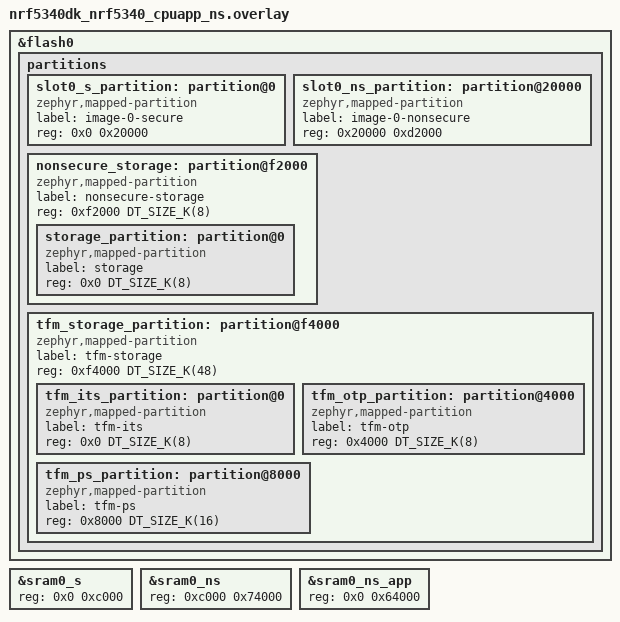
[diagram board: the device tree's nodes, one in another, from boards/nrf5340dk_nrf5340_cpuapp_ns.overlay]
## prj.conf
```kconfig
CONFIG_LOG=y

# Button and LED library
CONFIG_DK_LIBRARY=y
CONFIG_BT_LBS=y

CONFIG_BT=y
CONFIG_BT_DEVICE_NAME="Lamb_Idea_DK"

#  Include the Peripheral Role support
CONFIG_BT_PERIPHERAL=y

# Increase stack size for the main thread, System Workqueue, BT RX thread and TX buf count
CONFIG_SYSTEM_WORKQUEUE_STACK_SIZE=2048
CONFIG_MAIN_STACK_SIZE=2048
CONFIG_BT_RX_STACK_SIZE=2048
CONFIG_BT_BUF_CMD_TX_COUNT=2
```

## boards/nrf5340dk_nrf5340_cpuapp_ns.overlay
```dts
/*
 * Copyright (c) 2026 Nordic Semiconductor ASA
 *
 * SPDX-License-Identifier: LicenseRef-Nordic-5-Clause
 */

 /delete-node/ &boot_partition;
 /delete-node/ &slot0_partition;
 /delete-node/ &slot1_partition;
 /delete-node/ &tfm_its_partition;
 /delete-node/ &tfm_otp_partition;
 /delete-node/ &tfm_ps_partition;
 /delete-node/ &storage_partition;

 &flash0 {
	 partitions {
		 slot0_s_partition: partition@0 {
			 compatible = "zephyr,mapped-partition";
			 label = "image-0-secure";
			 reg = <0x0 0x20000>;
		 };

		 slot0_ns_partition: partition@20000 {
			 compatible = "zephyr,mapped-partition";
			 label = "image-0-nonsecure";
			 reg = <0x20000 0xd2000>;
		 };

		 nonsecure_storage: partition@f2000 {
			 compatible = "zephyr,mapped-partition";
			 label = "nonsecure-storage";
			 reg = <0xf2000 DT_SIZE_K(8)>;
			 ranges = <0x0 0xf2000 DT_SIZE_K(8)>;
			 #address-cells = <1>;
			 #size-cells = <1>;

			 storage_partition: partition@0 {
				 compatible = "zephyr,mapped-partition";
				 label = "storage";
				 reg = <0x0 DT_SIZE_K(8)>;
			 };
		 };

		 tfm_storage_partition: partition@f4000 {
			 compatible = "zephyr,mapped-partition";
			 label = "tfm-storage";
			 reg = <0xf4000 DT_SIZE_K(48)>;
			 ranges = <0x0 0xf4000 DT_SIZE_K(48)>;
			 #address-cells = <1>;
			 #size-cells = <1>;

			 tfm_its_partition: partition@0 {
				 compatible = "zephyr,mapped-partition";
				 label = "tfm-its";
				 reg = <0x0 DT_SIZE_K(8)>;
			 };

			 tfm_otp_partition: partition@4000 {
				 compatible = "zephyr,mapped-partition";
				 label = "tfm-otp";
				 reg = <0x4000 DT_SIZE_K(8)>;
			 };

			 tfm_ps_partition: partition@8000 {
				 compatible = "zephyr,mapped-partition";
				 label = "tfm-ps";
				 reg = <0x8000 DT_SIZE_K(16)>;
			 };
		 };
	 };
 };

 /*
  * TrustZone SRAM split from devicetree (region_defs.h for TF-M). The secure image uses
  * 48 KiB (0xc000) at the base of cpuapp SRAM (&sram0_s); NS RAM begins at 0x20000000 + 0xc000.
  * &sram0_ns spans 0x74000 bytes; &sram0_ns_app is 0x64000 because the top 0x10000 (64 KiB)
  * within that NS window is sram0_shared for application/network-core IPC
  * (nrf5340_shared_sram_partition.dtsi), i.e. 0x64000 + 0x10000 == 0x74000.
  */
 &sram0_s {
	 reg = <0x0 0xc000>;
 };

 &sram0_ns {
	 reg = <0xc000 0x74000>;
	 ranges = <0x0 0xc000 0x74000>;
 };

 &sram0_ns_app {
	 reg = <0x0 0x64000>;
 };
```

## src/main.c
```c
#include <zephyr/kernel.h>
#include <zephyr/logging/log.h>

#include <zephyr/bluetooth/bluetooth.h>
#include <zephyr/bluetooth/gap.h>
#include <zephyr/bluetooth/gatt.h>
#include <zephyr/bluetooth/uuid.h>
#include <zephyr/bluetooth/addr.h>
#include <zephyr/bluetooth/conn.h>

#include <dk_buttons_and_leds.h>

#define USER_BUTTON DK_BTN1_MSK
#define RUN_STATUS_LED DK_LED1
/* STEP 3.1 - Define an LED to show the connection status */
#define CONNECTION_STATUS_LED   DK_LED2
#define RUN_LED_BLINK_INTERVAL 1000

/* Create the advertising parameter for connectable advertising */
static const struct bt_le_adv_param *adv_param = BT_LE_ADV_PARAM(
	(BT_LE_ADV_OPT_CONN |
	 BT_LE_ADV_OPT_USE_IDENTITY), /* Connectable advertising and use identity address */
	BT_GAP_ADV_FAST_INT_MIN_1, /* 0x30 units, 48 units, 30ms */
	BT_GAP_ADV_FAST_INT_MAX_1, /* 0x60 units, 96 units, 60ms */
	NULL); /* Set to NULL for undirected advertising */

LOG_MODULE_REGISTER(main, 3);

#define DEVICE_NAME CONFIG_BT_DEVICE_NAME
#define DEVICE_NAME_LEN (sizeof(DEVICE_NAME) - 1)

struct bt_conn *my_conn = NULL;
static struct k_work adv_work;

/* Declare the advertising packet */
static const struct bt_data ad[] = {
	/* Set the advertising flags */
	BT_DATA_BYTES(BT_DATA_FLAGS, (BT_LE_AD_GENERAL | BT_LE_AD_NO_BREDR)),
	/* Set the advertising packet data  */
	BT_DATA(BT_DATA_NAME_COMPLETE, DEVICE_NAME, DEVICE_NAME_LEN),
};

/* Declare the scan response packet */
static const struct bt_data sd[] = {
	/* Include the 16-bytes (128-Bits) UUID of the LBS service in the scan response packet */
	BT_DATA_BYTES(BT_DATA_UUID128_ALL,
		      BT_UUID_128_ENCODE(0x00001523, 0x1212, 0xefde, 0x1523, 0x785feabcd123)),
};

/* Resume advertising after a disconnection */
static void adv_work_handler(struct k_work *work)
{
	int err = bt_le_adv_start(adv_param, ad, ARRAY_SIZE(ad), sd, ARRAY_SIZE(sd));

	if (err) {
		printk("Advertising failed to start (err %d)\n", err);
		return;
	}

	printk("Advertising successfully started\n");
}

static void advertising_start(void)
{
	k_work_submit(&adv_work);
}

/* Implement the callback functions */
void on_connected(struct bt_conn *conn, uint8_t err)
{
	if (err) {
		LOG_ERR("Connection error %d", err);
		return;
	}
	LOG_INF("Connected");
	my_conn = bt_conn_ref(conn);

	/* Turn the connection status LED on */
	// ...... maybe in ble/characteristics

	dk_set_led(CONNECTION_STATUS_LED, 1);
}

void on_disconnected(struct bt_conn *conn, uint8_t reason)
{
	LOG_INF("Disconnected. Reason %d", reason);
	bt_conn_unref(my_conn);

	/* Turn the connection status LED off */
	// ...... maybe in ble/characteristics

	dk_set_led(CONNECTION_STATUS_LED, 0);
}

static void on_recycled(void)
{

	// It typically means that you have encountered a disconnection, 
	// and that one of your connections has been unreferenced, 
	// meaning you can start advertising again.

	printk("Connection object available from previous conn. Disconnect is complete!\n");
	advertising_start();
}


// # Nordic: Note that in many of the Bluetooth Low Energy samples, 
// you will not see bt_conn_cb_register() being used. Instead, 
// they use the macro BT_CONN_CB_DEFINE(), 
// which will both define and register these callbacks.

// BT_CONN_CB_DEFINE(conn_callbacks) = {
// 	.recycled = recycled_cb,
// };

/* Declare the connection_callback structure */
struct bt_conn_cb connection_callbacks = {
	.connected              = on_connected,
	.disconnected           = on_disconnected,
	.recycled               = on_recycled,
};

int main(void)
{

	int blink_status = 0;
  int err;
	
  LOG_INF("Starting ble program!\n");

	err = dk_leds_init();
	if (err) {
		LOG_ERR("LEDs init failed (err %d)", err);
		return -1;
	}

  /* Change the random static address */
	bt_addr_le_t addr;
	err = bt_addr_le_from_str("FF:EE:DD:CC:BB:AA", "random", &addr);
	if (err) {
		printk("Invalid BT address (err %d)\n", err);
	}

	err = bt_id_create(&addr, NULL);
	if (err < 0) {
		printk("Creating new ID failed (err %d)\n", err);
	}

	/* Register our custom callbacks */
	err = bt_conn_cb_register(&connection_callbacks);
	if (err) {
		LOG_ERR("Connection callback register failed (err %d)", err);
	}

	err = bt_enable(NULL);
	if (err) {
		LOG_ERR("Bluetooth init failed (err %d)\n", err);
		return -1;
	}

	LOG_INF("Bluetooth initialized\n");

	/* Start connectable advertising */
	k_work_init(&adv_work, adv_work_handler);
	advertising_start();

	LOG_INF("Advertising successfully started\n");

	for (;;) {
		dk_set_led(RUN_STATUS_LED, (++blink_status) % 2);
		k_sleep(K_MSEC(RUN_LED_BLINK_INTERVAL));
	}

}
```
